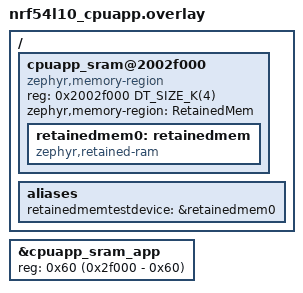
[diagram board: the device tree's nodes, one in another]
/ {
	cpuapp_sram@2002f000 {
		compatible = "zephyr,memory-region", "mmio-sram";
		reg = <0x2002f000 DT_SIZE_K(4)>;
		ranges = <0x0 0x2002f000 DT_SIZE_K(4)>;
		zephyr,memory-region = "RetainedMem";
		status = "okay";
		#address-cells = <1>;
		#size-cells = <1>;

		retainedmem0: retainedmem {
			compatible = "zephyr,retained-ram";
			status = "okay";
			ranges;
			#address-cells = <1>;
			#size-cells = <1>;
		};
	};

	aliases {
		retainedmemtestdevice = &retainedmem0;
	};
};

&cpuapp_sram_app {
	/* Shrink SRAM size to avoid overlap with retained memory region:
	 * 192 - 4 = 188KB = 0x2f000
	 */
	reg = <0x60 (0x2f000 - 0x60)>;
};
